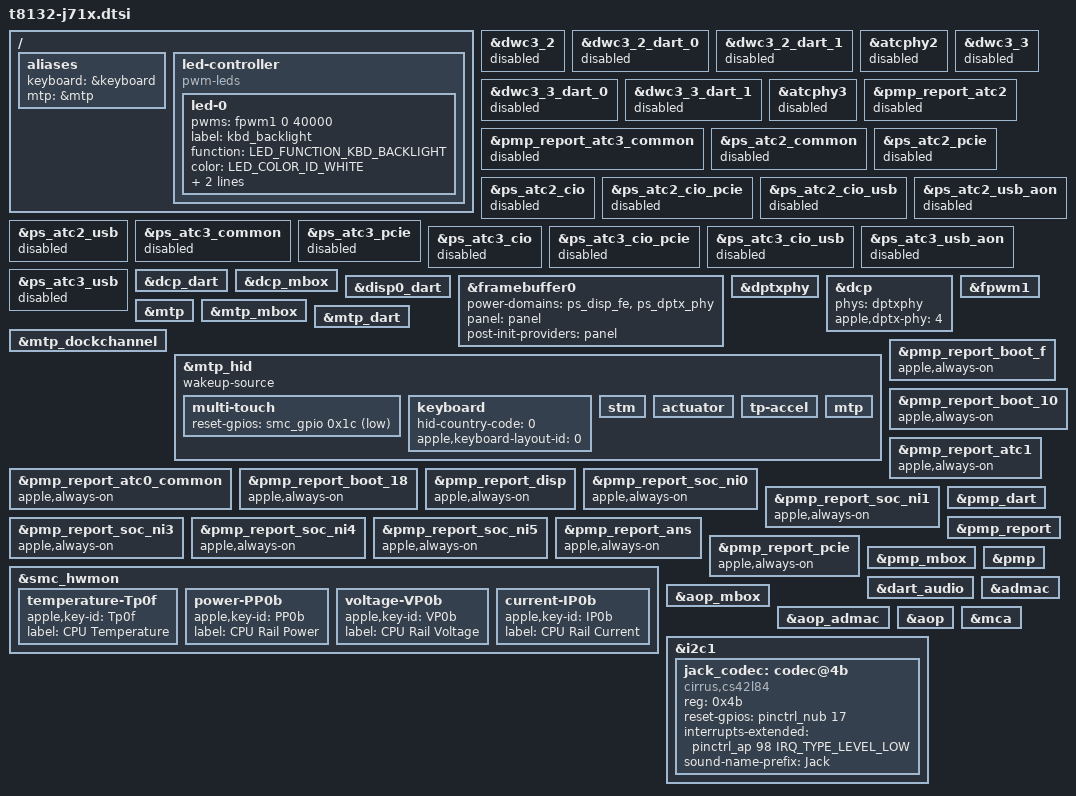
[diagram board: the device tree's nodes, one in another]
// SPDX-License-Identifier: GPL-2.0+ OR MIT
/*
 * Apple M4 MacBook Air (J713/J715) common board wiring.
 * Hardware compared against the captured J713 26.5.1 and J715 27.0 ADTs;
 * there is no firmware-matched pair in the collection yet.
 *
 * Copyright The Asahi Linux Contributors
 */

#include "t8132-mtp.dtsi"
#include "t8132-gpu.dtsi"
#include "t8132-aop.dtsi"
#include <dt-bindings/leds/common.h>

/*
 * J713/J715 have two USB-C ports (ATC0, ATC1). ATC2/ATC3 don't exist: both ADTs list
 * their power states without PS registers, so turning them on only fails.
 */
&dwc3_2 {
	status = "disabled";
};

&dwc3_2_dart_0 {
	status = "disabled";
};

&dwc3_2_dart_1 {
	status = "disabled";
};

&atcphy2 {
	status = "disabled";
};

&dwc3_3 {
	status = "disabled";
};

&dwc3_3_dart_0 {
	status = "disabled";
};

&dwc3_3_dart_1 {
	status = "disabled";
};

&atcphy3 {
	status = "disabled";
};

&pmp_report_atc2 {
	status = "disabled";
};

&pmp_report_atc3_common {
	status = "disabled";
};

&ps_atc2_common {
	status = "disabled";
};

&ps_atc2_pcie {
	status = "disabled";
};

&ps_atc2_cio {
	status = "disabled";
};

&ps_atc2_cio_pcie {
	status = "disabled";
};

&ps_atc2_cio_usb {
	status = "disabled";
};

&ps_atc2_usb_aon {
	status = "disabled";
};

&ps_atc2_usb {
	status = "disabled";
};

&ps_atc3_common {
	status = "disabled";
};

&ps_atc3_pcie {
	status = "disabled";
};

&ps_atc3_cio {
	status = "disabled";
};

&ps_atc3_cio_pcie {
	status = "disabled";
};

&ps_atc3_cio_usb {
	status = "disabled";
};

&ps_atc3_usb_aon {
	status = "disabled";
};

&ps_atc3_usb {
	status = "disabled";
};

/* Keep external DCPs off until their complete display path is supported. */
/ {
	aliases {
		/*
		 * No external display support yet. m1n1 enables every DCP behind a
		 * dcpextN alias that the ADT lists, but not its DARTs or mailbox;
		 * appledrm then never finishes init and boot blocks before userspace.
		 */
		/delete-property/ dcpext0;
		/delete-property/ dcpext1;
	};
};

&dcp_dart {
	status = "okay";
};

&dcp_mbox {
	status = "okay";
};

&disp0_dart {
	status = "okay";
};

&framebuffer0 {
	power-domains = <&ps_disp_fe>, <&ps_dptx_phy>;
	panel = <&panel>;
	post-init-providers = <&panel>;
};

/*
 * The internal eDP panel is driven through the DPTX PHY. DCP needs it
 * powered: without it the panel stays dark (backlight only), DPTX reports
 * FIFO errors, and DCP crashes on power-off touching the PHY registers.
 */
&dptxphy {
	status = "okay";
};

&dcp {
	phys = <&dptxphy>;
	phy-names = "dp-phy";
	apple,dptx-phy = <4>;
};

/*
 * DCP/disp0 reg, interrupts and power-gates match in both ADTs.
 * DPTX port 4 and PHY routing follow the working J713 (J715 inference).
 */
&dcp {
	status = "okay";
};

&fpwm1 {
	status = "okay";
};

&mtp {
	status = "okay";
};

&mtp_mbox {
	status = "okay";
};

&mtp_dart {
	status = "okay";
};

&mtp_dockchannel {
	status = "okay";
};

/*
 * ADT /arm-io/dockchannel-mtp: fifo-size/interrupts and transport children
 * match; multi-touch function-afe-reset is SMC gP1c on both boards.
 * HID descriptors/personality differ; load each board's own firmware.
 */
&mtp_hid {
	status = "okay";
	wakeup-source;

	multi-touch {
		/* ADT function-afe-reset: SMC gP1c, active-low AFE reset. */
		reset-gpios = <&smc_gpio 0x1c GPIO_ACTIVE_LOW>;
	};

	keyboard: keyboard {
		hid-country-code = <0>;
		apple,keyboard-layout-id = <0>;
	};

	stm {
	};

	actuator {
	};

	tp-accel {
	};

	mtp {
	};
};

/* ADT /arm-io/fpwm1/kbd-backlight; 40000 ns/255 retain J713 policy. */
/ {
	led-controller {
		compatible = "pwm-leds";
		led-0 {
			pwms = <&fpwm1 0 40000>;
			label = "kbd_backlight";
			function = LED_FUNCTION_KBD_BACKLIGHT;
			color = <LED_COLOR_ID_WHITE>;
			max-brightness = <255>;
			default-state = "keep";
		};
	};
};

/ {
	aliases {
		keyboard = &keyboard;
		/* Let the loader reserve and map the ADT MTP firmware segments. */
		mtp = &mtp;
	};
};

/*
 * ADT /arm-io/pmp reg/interrupts/power-gates and /arm-io/pmgr devices
 * id1 report numbers agree for the active domains on J713/J715.
 * Steady-vote policy is inherited from J713, not specified by the ADT;
 * its behavior on J715 remains unverified. The GPU vote follows its genpd.
 */
&pmp_report_boot_f {
	apple,always-on;
};

&pmp_report_boot_10 {
	apple,always-on;
};

&pmp_report_atc0_common {
	apple,always-on;
};

&pmp_report_atc1 {
	apple,always-on;
};

&pmp_report_boot_18 {
	apple,always-on;
};

&pmp_report_disp {
	apple,always-on;
};

&pmp_report_soc_ni0 {
	apple,always-on;
};

&pmp_report_soc_ni1 {
	apple,always-on;
};

&pmp_report_soc_ni3 {
	apple,always-on;
};

&pmp_report_soc_ni4 {
	apple,always-on;
};

&pmp_report_soc_ni5 {
	apple,always-on;
};

&pmp_report_ans {
	apple,always-on;
};

&pmp_report_pcie {
	apple,always-on;
};

&pmp_dart {
	status = "okay";
};

&pmp_report {
	status = "okay";
};

&pmp_mbox {
	status = "okay";
};

&pmp {
	status = "okay";
};

/*
 * The ADTs expose the same SMC, but do not enumerate its telemetry keys.
 * All keys/labels below are J713 observations or laptop conventions;
 * their availability and interpretation on J715 are guesses to validate.
 */
#include "t8132-j71x-thermal.dtsi"
#include "hwmon-common.dtsi"
#include "hwmon-laptop.dtsi"

/*
 * J713 SoC sensors, identified on the Air by behavior: under an all-core CPU
 * load Tp0f is among the hottest of the Tp keys (49 -> 106 C), and the PP0b/VP0b/IP0b rail follows
 * the load (1.5 -> 10 W, 0.61 -> 0.97 V, 2.4 -> 10.3 A; V * I matches P).
 * PMVR from hwmon-common doesn't exist on this SMC and is skipped.
 */
&smc_hwmon {
	temperature-Tp0f {
		apple,key-id = "Tp0f";
		label = "CPU Temperature";
	};
	power-PP0b {
		apple,key-id = "PP0b";
		label = "CPU Rail Power";
	};
	voltage-VP0b {
		apple,key-id = "VP0b";
		label = "CPU Rail Voltage";
	};
	current-IP0b {
		apple,key-id = "IP0b";
		label = "CPU Rail Current";
	};
};

&dart_audio {
	status = "okay";
};

&admac {
	status = "okay";
};

&aop_mbox {
	status = "okay";
};

&aop_admac {
	status = "okay";
};

&aop {
	status = "okay";
};

&i2c1 {
	status = "okay";

	jack_codec: codec@4b {
		compatible = "cirrus,cs42l84";
		reg = <0x4b>;
		#sound-dai-cells = <0>;
		reset-gpios = <&pinctrl_nub 17 GPIO_ACTIVE_HIGH>;
		interrupts-extended = <&pinctrl_ap 98 IRQ_TYPE_LEVEL_LOW>;
		sound-name-prefix = "Jack";
	};
};

/*
 * ADT /arm-io/i2c1/audio-codec-output: cs42l84 at 0x4b, NUB GPIO 17
 * reset and AP GPIO 98 IRQ. Audio-hp mic selectors/data-sources/reg and
 * /arm-io/admac-leap-ns agree, including LEAP RX 1 and 48 kHz.
 */
&mca {
	status = "okay";
};
